AUTOSAR XML (schema 4-2-2)
package /STELLANTIS/EPT/ASWCs
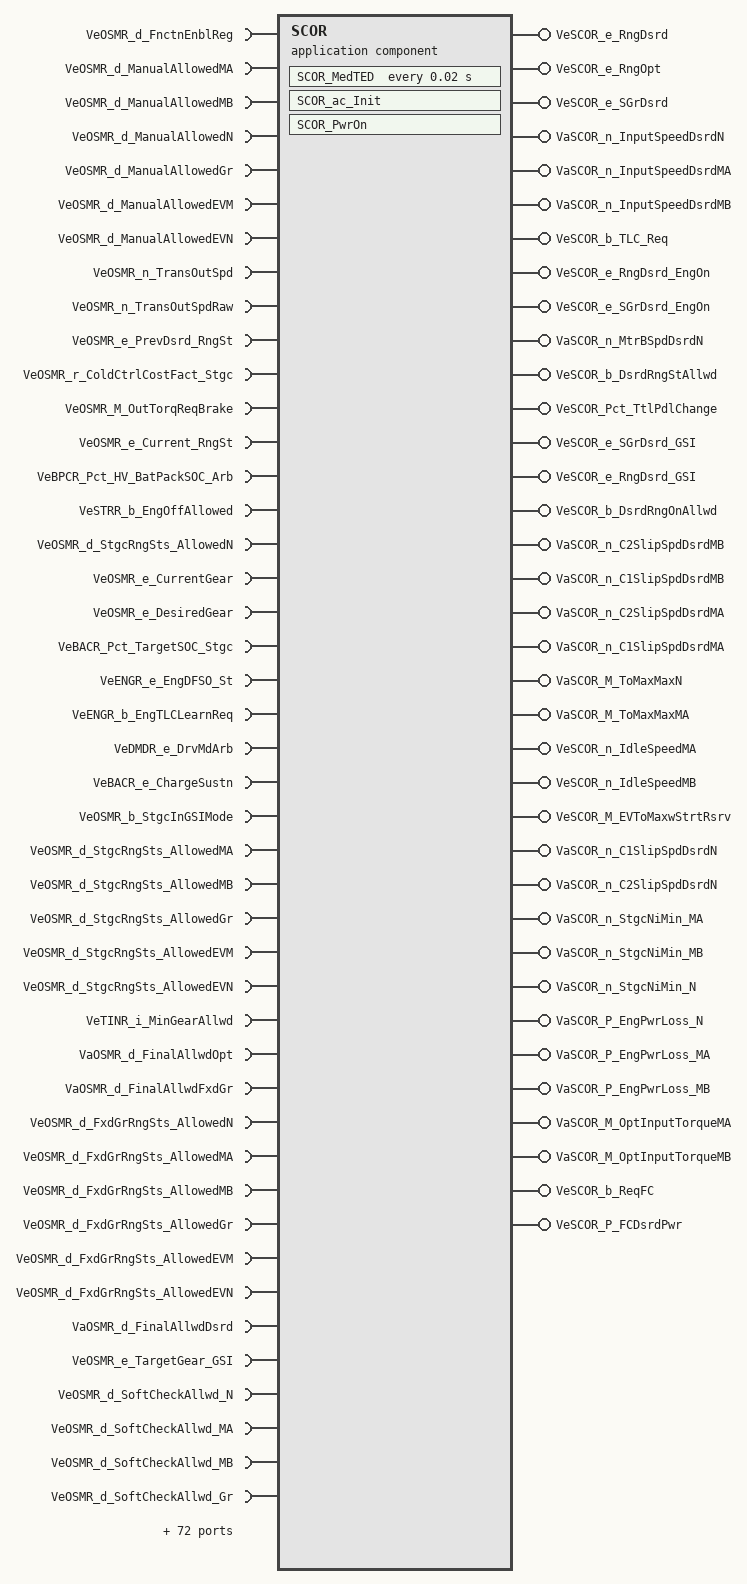
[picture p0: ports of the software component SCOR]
  application sw component type SCOR
    99 x require port:
      VeOSMR_d_FnctnEnblReg: nonqueued-receiver-com-spec{data-element=Value, init-value=0}, required-interface=VeOSMR_d_FnctnEnblReg
      VeOSMR_d_ManualAllowedMA: nonqueued-receiver-com-spec{data-element=Value, init-value=0}, required-interface=VeOSMR_d_ManualAllowedMA
      VeOSMR_d_ManualAllowedMB: nonqueued-receiver-com-spec{data-element=Value, init-value=0}, required-interface=VeOSMR_d_ManualAllowedMB
      VeOSMR_d_ManualAllowedN: nonqueued-receiver-com-spec{data-element=Value, init-value=0}, required-interface=VeOSMR_d_ManualAllowedN
      VeOSMR_d_ManualAllowedGr: nonqueued-receiver-com-spec{data-element=Value, init-value=0}, required-interface=VeOSMR_d_ManualAllowedGr
      VeOSMR_d_ManualAllowedEVM: nonqueued-receiver-com-spec{data-element=Value, init-value=0}, required-interface=VeOSMR_d_ManualAllowedEVM
      VeOSMR_d_ManualAllowedEVN: nonqueued-receiver-com-spec{data-element=Value, init-value=0}, required-interface=VeOSMR_d_ManualAllowedEVN
      VeOSMR_n_TransOutSpd: nonqueued-receiver-com-spec{data-element=Value, init-value=0}, required-interface=VeOSMR_n_TransOutSpd
      VeOSMR_n_TransOutSpdRaw: variation-point={short-label=vpVeOSMR_n_TransOutSpdRaw, sw-syscond=1}, nonqueued-receiver-com-spec{data-element=Value, init-value=0}, required-interface=VeOSMR_n_TransOutSpdRaw
      VeOSMR_e_PrevDsrd_RngSt: nonqueued-receiver-com-spec{data-element=Value, init-value=CeSCOR_e_SG_Neutral}, required-interface=VeOSMR_e_PrevDsrd_RngSt
      VeOSMR_r_ColdCtrlCostFact_Stgc: nonqueued-receiver-com-spec{data-element=Value, init-value=0}, required-interface=VeOSMR_r_ColdCtrlCostFact_Stgc
      VeOSMR_M_OutTorqReqBrake: nonqueued-receiver-com-spec{data-element=Value, init-value=0}, required-interface=VeOSMR_M_OutTorqReqBrake
      VeOSMR_e_Current_RngSt: nonqueued-receiver-com-spec{data-element=Value, init-value=CeSCOR_e_SG_Neutral}, required-interface=VeOSMR_e_Current_RngSt
      VeBPCR_Pct_HV_BatPackSOC_Arb: nonqueued-receiver-com-spec{data-element=Value, init-value=0}, required-interface=VeBPCR_Pct_HV_BatPackSOC_Arb
      VeSTRR_b_EngOffAllowed: nonqueued-receiver-com-spec{data-element=Value, init-value=0}, required-interface=VeSTRR_b_EngOffAllowed
      VeOSMR_d_StgcRngSts_AllowedN: nonqueued-receiver-com-spec{data-element=Value, init-value=0}, required-interface=VeOSMR_d_StgcRngSts_AllowedN
      VeOSMR_e_CurrentGear: nonqueued-receiver-com-spec{data-element=Value, init-value=CeTRNR_e_Neutral}, required-interface=VeOSMR_e_CurrentGear
      VeOSMR_e_DesiredGear: nonqueued-receiver-com-spec{data-element=Value, init-value=CeOHSR_e_SG_Reverse}, required-interface=VeOSMR_e_DesiredGear
      VeBACR_Pct_TargetSOC_Stgc: nonqueued-receiver-com-spec{data-element=Value, init-value=0}, required-interface=VeBACR_Pct_TargetSOC_Stgc
      VeENGR_e_EngDFSO_St: nonqueued-receiver-com-spec{data-element=Value, init-value=CeENGR_e_DFSO_Disabled}, required-interface=VeENGR_e_EngDFSO_St
      VeENGR_b_EngTLCLearnReq: nonqueued-receiver-com-spec{data-element=Value, init-value=0}, required-interface=VeENGR_b_EngTLCLearnReq
      VeDMDR_e_DrvMdArb: nonqueued-receiver-com-spec{data-element=Value, init-value=CeDMDR_e_NoDrvMd}, required-interface=VeDMDR_e_DrvMdArb
      VeBACR_e_ChargeSustn: nonqueued-receiver-com-spec{data-element=Value, init-value=CeBACR_e_ChargeSustaining}, required-interface=VeBACR_e_ChargeSustn
      VeOSMR_b_StgcInGSIMode: nonqueued-receiver-com-spec{data-element=Value, init-value=0}, required-interface=VeOSMR_b_StgcInGSIMode
      VeOSMR_d_StgcRngSts_AllowedMA: nonqueued-receiver-com-spec{data-element=Value, init-value=0}, required-interface=VeOSMR_d_StgcRngSts_AllowedMA
      VeOSMR_d_StgcRngSts_AllowedMB: nonqueued-receiver-com-spec{data-element=Value, init-value=0}, required-interface=VeOSMR_d_StgcRngSts_AllowedMB
      VeOSMR_d_StgcRngSts_AllowedGr: nonqueued-receiver-com-spec{data-element=Value, init-value=0}, required-interface=VeOSMR_d_StgcRngSts_AllowedGr
      VeOSMR_d_StgcRngSts_AllowedEVM: nonqueued-receiver-com-spec{data-element=Value, init-value=0}, required-interface=VeOSMR_d_StgcRngSts_AllowedEVM
      VeOSMR_d_StgcRngSts_AllowedEVN: nonqueued-receiver-com-spec{data-element=Value, init-value=0}, required-interface=VeOSMR_d_StgcRngSts_AllowedEVN
      VeTINR_i_MinGearAllwd: nonqueued-receiver-com-spec{data-element=Value, init-value=0}, required-interface=VeTINR_i_MinGearAllwd
      VaOSMR_d_FinalAllwdOpt: nonqueued-receiver-com-spec{data-element=Value, init-value=6 x 0}, required-interface=VaOSMR_d_FinalAllwdOpt
      VaOSMR_d_FinalAllwdFxdGr: nonqueued-receiver-com-spec{data-element=Value, init-value=6 x 0}, required-interface=VaOSMR_d_FinalAllwdFxdGr
      VeOSMR_d_FxdGrRngSts_AllowedN: nonqueued-receiver-com-spec{data-element=Value, init-value=0}, required-interface=VeOSMR_d_FxdGrRngSts_AllowedN
      VeOSMR_d_FxdGrRngSts_AllowedMA: nonqueued-receiver-com-spec{data-element=Value, init-value=0}, required-interface=VeOSMR_d_FxdGrRngSts_AllowedMA
      VeOSMR_d_FxdGrRngSts_AllowedMB: nonqueued-receiver-com-spec{data-element=Value, init-value=0}, required-interface=VeOSMR_d_FxdGrRngSts_AllowedMB
      VeOSMR_d_FxdGrRngSts_AllowedGr: nonqueued-receiver-com-spec{data-element=Value, init-value=0}, required-interface=VeOSMR_d_FxdGrRngSts_AllowedGr
      VeOSMR_d_FxdGrRngSts_AllowedEVM: nonqueued-receiver-com-spec{data-element=Value, init-value=0}, required-interface=VeOSMR_d_FxdGrRngSts_AllowedEVM
      VeOSMR_d_FxdGrRngSts_AllowedEVN: nonqueued-receiver-com-spec{data-element=Value, init-value=0}, required-interface=VeOSMR_d_FxdGrRngSts_AllowedEVN
      VaOSMR_d_FinalAllwdDsrd: nonqueued-receiver-com-spec{data-element=Value, init-value=6 x 0}, required-interface=VaOSMR_d_FinalAllwdDsrd
      VeOSMR_e_TargetGear_GSI: nonqueued-receiver-com-spec{data-element=Value, init-value=CeTRNR_e_Neutral}, required-interface=VeOSMR_e_TargetGear_GSI
      VeOSMR_d_SoftCheckAllwd_N: nonqueued-receiver-com-spec{data-element=Value, init-value=0}, required-interface=VeOSMR_d_SoftCheckAllwd_N
      VeOSMR_d_SoftCheckAllwd_MA: nonqueued-receiver-com-spec{data-element=Value, init-value=0}, required-interface=VeOSMR_d_SoftCheckAllwd_MA
      VeOSMR_d_SoftCheckAllwd_MB: nonqueued-receiver-com-spec{data-element=Value, init-value=0}, required-interface=VeOSMR_d_SoftCheckAllwd_MB
      VeOSMR_d_SoftCheckAllwd_Gr: nonqueued-receiver-com-spec{data-element=Value, init-value=0}, required-interface=VeOSMR_d_SoftCheckAllwd_Gr
      VeOSMR_d_SoftCheckAllwd_EVM: nonqueued-receiver-com-spec{data-element=Value, init-value=0}, required-interface=VeOSMR_d_SoftCheckAllwd_EVM
      VeOSMR_d_SoftCheckAllwd_EVN: nonqueued-receiver-com-spec{data-element=Value, init-value=0}, required-interface=VeOSMR_d_SoftCheckAllwd_EVN
      VeEOCR_r_CatTempMaintFact: nonqueued-receiver-com-spec{data-element=Value, init-value=0}, required-interface=VeEOCR_r_CatTempMaintFact
      VeOSMR_P_HVBatt_Bus_Min: nonqueued-receiver-com-spec{data-element=Value, init-value=0}, required-interface=VeOSMR_P_HVBatt_Bus_Min
      VeOSMR_P_HVBatt_Bus_Max: nonqueued-receiver-com-spec{data-element=Value, init-value=0}, required-interface=VeOSMR_P_HVBatt_Bus_Max
      VeOSMR_P_HV_AccPwr: nonqueued-receiver-com-spec{data-element=Value, init-value=0}, required-interface=VeOSMR_P_HV_AccPwr
      VeOSMR_M_OutTorqReqAccel: nonqueued-receiver-com-spec{data-element=Value, init-value=0}, required-interface=VeOSMR_M_OutTorqReqAccel
      VeAPSR_Pct_AccelPedalEffPosition: nonqueued-receiver-com-spec{data-element=Value, init-value=0}, required-interface=VeAPSR_Pct_AccelPedalEffPosition
      VaOSMR_i_MinGrPerRngSt: nonqueued-receiver-com-spec{data-element=Value, init-value=6 x 0}, required-interface=VaOSMR_i_MinGrPerRngSt
      VaOSMR_i_MaxGrPerRngSt: nonqueued-receiver-com-spec{data-element=Value, init-value=6 x 0}, required-interface=VaOSMR_i_MaxGrPerRngSt
      VeOSMR_b_1DOptEnbl: variation-point={short-label=vpVeOSMR_b_1DOptEnbl, sw-syscond=1}, nonqueued-receiver-com-spec{data-element=Value, init-value=0}, required-interface=VeOSMR_b_1DOptEnbl
      VeTHMR_P_FCPSThrmlPwr_MaxAllwd: nonqueued-receiver-com-spec{data-element=Value, init-value=0}, required-interface=VeTHMR_P_FCPSThrmlPwr_MaxAllwd
      VeFCPR_P_FCPS_ReqdMinFCPSPwr: nonqueued-receiver-com-spec{data-element=Value, init-value=0}, required-interface=VeFCPR_P_FCPS_ReqdMinFCPSPwr
      VeFCPR_P_FCPS_MaxAvailFCPSPwr: nonqueued-receiver-com-spec{data-element=Value, init-value=0}, required-interface=VeFCPR_P_FCPS_MaxAvailFCPSPwr
      VaOMAR_n_InputSpeedDsrdMA: nonqueued-receiver-com-spec{data-element=Value, init-value=9 x 0}, required-interface=VaOMAR_n_InputSpeedDsrdMA
      VaOMAR_M_OptInputTorqueMA: nonqueued-receiver-com-spec{data-element=Value, init-value=9 x 0}, required-interface=VaOMAR_M_OptInputTorqueMA
      VaOMAR_M_ToMaxMaxMA: nonqueued-receiver-com-spec{data-element=Value, init-value=9 x 0}, required-interface=VaOMAR_M_ToMaxMaxMA
      VaOMAR_n_C1SlipSpdDsrdMA: nonqueued-receiver-com-spec{data-element=Value, init-value=9 x 0}, required-interface=VaOMAR_n_C1SlipSpdDsrdMA
      VaOMAR_n_C2SlipSpdDsrdMA: nonqueued-receiver-com-spec{data-element=Value, init-value=9 x 0}, required-interface=VaOMAR_n_C2SlipSpdDsrdMA
      VaOMAR_OptBatPwrBrkRaw_MA: variation-point={short-label=vpVaOMAR_OptBatPwrBrkRaw_MA, sw-syscond=1}, nonqueued-receiver-com-spec{data-element=Value, init-value=9 x 0}, required-interface=VaOMAR_OptBatPwrBrkRaw_MA
      VaOMAR_n_StgcNiMin_MA: nonqueued-receiver-com-spec{data-element=Value, init-value=9 x 0}, required-interface=VaOMAR_n_StgcNiMin_MA
      VaOMAR_P_EngPwrLoss_MA: nonqueued-receiver-com-spec{data-element=Value, init-value=9 x 0}, required-interface=VaOMAR_P_EngPwrLoss_MA
      VaOMNR_PLossOptRaw_N: nonqueued-receiver-com-spec{data-element=Value, init-value=9 x 0}, required-interface=VaOMNR_PLossOptRaw_N
      VaOMAR_PLossOptRaw_MA: nonqueued-receiver-com-spec{data-element=Value, init-value=9 x 0}, required-interface=VaOMAR_PLossOptRaw_MA
      VaOMBR_PLossOptRaw_MB: nonqueued-receiver-com-spec{data-element=Value, init-value=9 x 0}, required-interface=VaOMBR_PLossOptRaw_MB
      VaOMBR_PLossOptRaw_MBNR: nonqueued-receiver-com-spec{data-element=Value, init-value=9 x 0}, required-interface=VaOMBR_PLossOptRaw_MBNR
      VaOGRR_PLossOptRaw_GrA: nonqueued-receiver-com-spec{data-element=Value, init-value=9 x 0}, required-interface=VaOGRR_PLossOptRaw_GrA
      VaOGRR_PLossOptRaw_Gr: nonqueued-receiver-com-spec{data-element=Value, init-value=9 x 0}, required-interface=VaOGRR_PLossOptRaw_Gr
      VaOEVR_PLossOptRaw_EVM: nonqueued-receiver-com-spec{data-element=Value, init-value=9 x 0}, required-interface=VaOEVR_PLossOptRaw_EVM
      VeOMAR_n_IdleSpeedMA: nonqueued-receiver-com-spec{data-element=Value, init-value=0}, required-interface=VeOMAR_n_IdleSpeedMA
      VaOMBR_n_InputSpeedDsrdMB: nonqueued-receiver-com-spec{data-element=Value, init-value=9 x 0}, required-interface=VaOMBR_n_InputSpeedDsrdMB
      VaOMBR_n_C1SlipSpdDsrdMB: nonqueued-receiver-com-spec{data-element=Value, init-value=9 x 0}, required-interface=VaOMBR_n_C1SlipSpdDsrdMB
      VaOMBR_n_C2SlipSpdDsrdMB: nonqueued-receiver-com-spec{data-element=Value, init-value=9 x 0}, required-interface=VaOMBR_n_C2SlipSpdDsrdMB
      VaOMBR_OptBatPwrBrkRaw_MBNR: variation-point={short-label=vpVaOMBR_OptBatPwrBrkRaw_MBNR, sw-syscond=1}, nonqueued-receiver-com-spec{data-element=Value, init-value=9 x 0}, required-interface=VaOMBR_OptBatPwrBrkRaw_MBNR
      VaOMBR_OptBatPwrBrkRaw_MB: variation-point={short-label=vpVaOMBR_OptBatPwrBrkRaw_MB, sw-syscond=1}, nonqueued-receiver-com-spec{data-element=Value, init-value=9 x 0}, required-interface=VaOMBR_OptBatPwrBrkRaw_MB
      VaOMBR_M_OptInputTorqueMB: nonqueued-receiver-com-spec{data-element=Value, init-value=9 x 0}, required-interface=VaOMBR_M_OptInputTorqueMB
      VaOMBR_n_StgcNiMin_MB: nonqueued-receiver-com-spec{data-element=Value, init-value=9 x 0}, required-interface=VaOMBR_n_StgcNiMin_MB
      VaOMBR_P_EngPwrLoss_MB: nonqueued-receiver-com-spec{data-element=Value, init-value=9 x 0}, required-interface=VaOMBR_P_EngPwrLoss_MB
      VeOMBR_n_IdleSpeedMB: nonqueued-receiver-com-spec{data-element=Value, init-value=0}, required-interface=VeOMBR_n_IdleSpeedMB
      VaOMNR_n_InputSpeedDsrdN: variation-point={short-label=vpVaOMNR_n_InputSpeedDsrdN, sw-syscond=1}, nonqueued-receiver-com-spec{data-element=Value, init-value=9 x 0}, required-interface=VaOMNR_n_InputSpeedDsrdN
      VaOMNR_n_MtrBSpdDsrdN: variation-point={short-label=vpVaOMNR_n_MtrBSpdDsrdN, sw-syscond=1}, nonqueued-receiver-com-spec{data-element=Value, init-value=9 x 0}, required-interface=VaOMNR_n_MtrBSpdDsrdN
      VaOMNR_n_C1SlipSpdDsrdN: nonqueued-receiver-com-spec{data-element=Value, init-value=9 x 0}, required-interface=VaOMNR_n_C1SlipSpdDsrdN
      VaOMNR_n_C2SlipSpdDsrdN: nonqueued-receiver-com-spec{data-element=Value, init-value=9 x 0}, required-interface=VaOMNR_n_C2SlipSpdDsrdN
      VaOMNR_M_ToMaxMaxN: nonqueued-receiver-com-spec{data-element=Value, init-value=9 x 0}, required-interface=VaOMNR_M_ToMaxMaxN
      VaOMNR_n_StgcNiMin_N: nonqueued-receiver-com-spec{data-element=Value, init-value=9 x 0}, required-interface=VaOMNR_n_StgcNiMin_N
      VaOMNR_M_OptInputTorqueN: variation-point={short-label=vpVaOMNR_M_OptInputTorqueN, sw-syscond=1}, nonqueued-receiver-com-spec{data-element=Value, init-value=9 x 0}, required-interface=VaOMNR_M_OptInputTorqueN
      VaOMNR_P_EngPwrLoss_N: variation-point={short-label=vpVaOMNR_P_EngPwrLoss_N, sw-syscond=1}, nonqueued-receiver-com-spec{data-element=Value, init-value=9 x 0}, required-interface=VaOMNR_P_EngPwrLoss_N
      VaOMNR_OptBatPwrBrkRaw_N: variation-point={short-label=vpVaOMNR_OptBatPwrBrkRaw_N, sw-syscond=1}, nonqueued-receiver-com-spec{data-element=Value, init-value=9 x 0}, required-interface=VaOMNR_OptBatPwrBrkRaw_N
      VaOGRR_OptBatPwrBrkRaw_GrA: variation-point={short-label=vpVaOGRR_OptBatPwrBrkRaw_GrA, sw-syscond=1}, nonqueued-receiver-com-spec{data-element=Value, init-value=9 x 0}, required-interface=VaOGRR_OptBatPwrBrkRaw_GrA
      VaOGRR_OptBatPwrBrkRaw_Gr: variation-point={short-label=vpVaOGRR_OptBatPwrBrkRaw_Gr, sw-syscond=1}, nonqueued-receiver-com-spec{data-element=Value, init-value=9 x 0}, required-interface=VaOGRR_OptBatPwrBrkRaw_Gr
      VaOEVR_PLossOptRaw_EVN: nonqueued-receiver-com-spec{data-element=Value, init-value=9 x 0}, required-interface=VaOEVR_PLossOptRaw_EVN
      VaOEVR_P_OptBattPwrEVM_Raw: nonqueued-receiver-com-spec{data-element=Value, init-value=9 x 0}, required-interface=VaOEVR_P_OptBattPwrEVM_Raw
      VaOEVR_P_OptBattPwrEVN_Raw: nonqueued-receiver-com-spec{data-element=Value, init-value=9 x 0}, required-interface=VaOEVR_P_OptBattPwrEVN_Raw
      VaOEVR_OptBatPwrBrkRaw_EVM: variation-point={short-label=vpVaOEVR_OptBatPwrBrkRaw_EVM, sw-syscond=1}, nonqueued-receiver-com-spec{data-element=Value, init-value=9 x 0}, required-interface=VaOEVR_OptBatPwrBrkRaw_EVM
      VaOEVR_OptBatPwrBrkRaw_EVN: variation-point={short-label=vpVaOEVR_OptBatPwrBrkRaw_EVN, sw-syscond=1}, nonqueued-receiver-com-spec{data-element=Value, init-value=9 x 0}, required-interface=VaOEVR_OptBatPwrBrkRaw_EVN
    36 x provide port:
      VeSCOR_e_RngDsrd: nonqueued-sender-com-spec{data-element=Value, init-value=CeSCOR_e_SG_Neutral}, provided-interface=VeSCOR_e_RngDsrd
      VeSCOR_e_RngOpt: nonqueued-sender-com-spec{data-element=Value, init-value=CeSCOR_e_SG_Neutral}, provided-interface=VeSCOR_e_RngOpt
      VeSCOR_e_SGrDsrd: nonqueued-sender-com-spec{data-element=Value, init-value=CeSCOR_e_SG_1}, provided-interface=VeSCOR_e_SGrDsrd
      VaSCOR_n_InputSpeedDsrdN: nonqueued-sender-com-spec{data-element=Value, init-value=9 x 0}, provided-interface=VaSCOR_n_InputSpeedDsrdN
      VaSCOR_n_InputSpeedDsrdMA: nonqueued-sender-com-spec{data-element=Value, init-value=9 x 0}, provided-interface=VaSCOR_n_InputSpeedDsrdMA
      VaSCOR_n_InputSpeedDsrdMB: nonqueued-sender-com-spec{data-element=Value, init-value=9 x 0}, provided-interface=VaSCOR_n_InputSpeedDsrdMB
      VeSCOR_b_TLC_Req: nonqueued-sender-com-spec{data-element=Value, init-value=0}, provided-interface=VeSCOR_b_TLC_Req
      VeSCOR_e_RngDsrd_EngOn: nonqueued-sender-com-spec{data-element=Value, init-value=CeSCOR_e_SG_Neutral}, provided-interface=VeSCOR_e_RngDsrd_EngOn
      VeSCOR_e_SGrDsrd_EngOn: nonqueued-sender-com-spec{data-element=Value, init-value=CeSCOR_e_SG_1}, provided-interface=VeSCOR_e_SGrDsrd_EngOn
      VaSCOR_n_MtrBSpdDsrdN: nonqueued-sender-com-spec{data-element=Value, init-value=9 x 0}, provided-interface=VaSCOR_n_MtrBSpdDsrdN
      VeSCOR_b_DsrdRngStAllwd: nonqueued-sender-com-spec{data-element=Value, init-value=0}, provided-interface=VeSCOR_b_DsrdRngStAllwd
      VeSCOR_Pct_TtlPdlChange: nonqueued-sender-com-spec{data-element=Value, init-value=0}, provided-interface=VeSCOR_Pct_TtlPdlChange
      VeSCOR_e_SGrDsrd_GSI: nonqueued-sender-com-spec{data-element=Value, init-value=CeSCOR_e_SG_1}, provided-interface=VeSCOR_e_SGrDsrd_GSI
      VeSCOR_e_RngDsrd_GSI: nonqueued-sender-com-spec{data-element=Value, init-value=CeSCOR_e_SG_Neutral}, provided-interface=VeSCOR_e_RngDsrd_GSI
      VeSCOR_b_DsrdRngOnAllwd: nonqueued-sender-com-spec{data-element=Value, init-value=0}, provided-interface=VeSCOR_b_DsrdRngOnAllwd
      VaSCOR_n_C2SlipSpdDsrdMB: nonqueued-sender-com-spec{data-element=Value, init-value=9 x 0}, provided-interface=VaSCOR_n_C2SlipSpdDsrdMB
      VaSCOR_n_C1SlipSpdDsrdMB: nonqueued-sender-com-spec{data-element=Value, init-value=9 x 0}, provided-interface=VaSCOR_n_C1SlipSpdDsrdMB
      VaSCOR_n_C2SlipSpdDsrdMA: nonqueued-sender-com-spec{data-element=Value, init-value=9 x 0}, provided-interface=VaSCOR_n_C2SlipSpdDsrdMA
      VaSCOR_n_C1SlipSpdDsrdMA: nonqueued-sender-com-spec{data-element=Value, init-value=9 x 0}, provided-interface=VaSCOR_n_C1SlipSpdDsrdMA
      VaSCOR_M_ToMaxMaxN: nonqueued-sender-com-spec{data-element=Value, init-value=9 x 0}, provided-interface=VaSCOR_M_ToMaxMaxN
      VaSCOR_M_ToMaxMaxMA: nonqueued-sender-com-spec{data-element=Value, init-value=9 x 0}, provided-interface=VaSCOR_M_ToMaxMaxMA
      VeSCOR_n_IdleSpeedMA: nonqueued-sender-com-spec{data-element=Value, init-value=0}, provided-interface=VeSCOR_n_IdleSpeedMA
      VeSCOR_n_IdleSpeedMB: nonqueued-sender-com-spec{data-element=Value, init-value=0}, provided-interface=VeSCOR_n_IdleSpeedMB
      VeSCOR_M_EVToMaxwStrtRsrv: nonqueued-sender-com-spec{data-element=Value, init-value=0}, provided-interface=VeSCOR_M_EVToMaxwStrtRsrv
      VaSCOR_n_C1SlipSpdDsrdN: nonqueued-sender-com-spec{data-element=Value, init-value=9 x 0}, provided-interface=VaSCOR_n_C1SlipSpdDsrdN
      VaSCOR_n_C2SlipSpdDsrdN: nonqueued-sender-com-spec{data-element=Value, init-value=9 x 0}, provided-interface=VaSCOR_n_C2SlipSpdDsrdN
      VaSCOR_n_StgcNiMin_MA: nonqueued-sender-com-spec{data-element=Value, init-value=9 x 0}, provided-interface=VaSCOR_n_StgcNiMin_MA
      VaSCOR_n_StgcNiMin_MB: nonqueued-sender-com-spec{data-element=Value, init-value=9 x 0}, provided-interface=VaSCOR_n_StgcNiMin_MB
      VaSCOR_n_StgcNiMin_N: nonqueued-sender-com-spec{data-element=Value, init-value=9 x 0}, provided-interface=VaSCOR_n_StgcNiMin_N
      VaSCOR_P_EngPwrLoss_N: nonqueued-sender-com-spec{data-element=Value, init-value=9 x 0}, provided-interface=VaSCOR_P_EngPwrLoss_N
      VaSCOR_P_EngPwrLoss_MA: nonqueued-sender-com-spec{data-element=Value, init-value=9 x 0}, provided-interface=VaSCOR_P_EngPwrLoss_MA
      VaSCOR_P_EngPwrLoss_MB: nonqueued-sender-com-spec{data-element=Value, init-value=9 x 0}, provided-interface=VaSCOR_P_EngPwrLoss_MB
      VaSCOR_M_OptInputTorqueMA: nonqueued-sender-com-spec{data-element=Value, init-value=9 x 0}, provided-interface=VaSCOR_M_OptInputTorqueMA
      VaSCOR_M_OptInputTorqueMB: nonqueued-sender-com-spec{data-element=Value, init-value=9 x 0}, provided-interface=VaSCOR_M_OptInputTorqueMB
      VeSCOR_b_ReqFC: nonqueued-sender-com-spec{data-element=Value, init-value=0}, provided-interface=VeSCOR_b_ReqFC
      VeSCOR_P_FCDsrdPwr: nonqueued-sender-com-spec{data-element=Value, init-value=0}, provided-interface=VeSCOR_P_FCDsrdPwr
    17 x require port:
      CaOPTR_r_ZeroArray: parameter-require-com-spec{init-value=CaOPTR_r_ZeroArray_CaOPTR_r_ZeroArray:[CaOPTR_r_ZeroArray_CaOPTR_r_ZeroArray_rt_Array_Float_9_1:0, CaOPTR_r_ZeroArray_CaOPTR_r_ZeroArray_rt_Array_Float_9_2:0, CaOPTR_r_ZeroArray_CaOPTR_r_ZeroArray_rt_Array_Float_9_3:0, CaOPTR_r_ZeroArray_CaOPTR_r_ZeroArray_rt_Array_Float_9_4:0, CaOPTR_r_ZeroArray_CaOPTR_r_ZeroArray_rt_Array_Float_9_5:0, CaOPTR_r_ZeroArray_CaOPTR_r_ZeroArray_rt_Array_Float_9_6:0, CaOPTR_r_ZeroArray_CaOPTR_r_ZeroArray_rt_Array_Float_9_7:0, CaOPTR_r_ZeroArray_CaOPTR_r_ZeroArray_rt_Array_Float_9_8:0, CaOPTR_r_ZeroArray_CaOPTR_r_ZeroArray_rt_Array_Float_9_9:0], parameter=CaOPTR_r_ZeroArray}, required-interface=CaOPTR_r_ZeroArray
      HaOPTR_n_InitInputSpdDsrdMA: parameter-require-com-spec{init-value=9 x 500, parameter=HaOPTR_n_InitInputSpdDsrdMA}, required-interface=HaOPTR_n_InitInputSpdDsrdMA
      HaOPTR_n_InitInputSpdDsrdMB: parameter-require-com-spec{init-value=9 x 500, parameter=HaOPTR_n_InitInputSpdDsrdMB}, required-interface=HaOPTR_n_InitInputSpdDsrdMB
      HaOPTR_n_InitInputSpdDsrdN: parameter-require-com-spec{init-value=9 x 500, parameter=HaOPTR_n_InitInputSpdDsrdN}, required-interface=HaOPTR_n_InitInputSpdDsrdN
      KeOPTR_P_DfltOptCost: parameter-require-com-spec{init-value=KeOPTR_P_DfltOptCost_KeOPTR_P_DfltOptCost:1000000, parameter=KeOPTR_P_DfltOptCost}, required-interface=KeOPTR_P_DfltOptCost
      HaOPTR_b_OptBatPwrBrk_EVM_Enbl: parameter-require-com-spec{init-value=HaOPTR_b_OptBatPwrBrk_EVM_Enbl_HaOPTR_b_OptBatPwrBrk_EVM_Enbl:[HaOPTR_b_OptBatPwrBrk_EVM_Enbl_HaOPTR_b_OptBatPwrBrk_EVM_Enbl_rt_Array_Boolean_9_1:0, HaOPTR_b_OptBatPwrBrk_EVM_Enbl_HaOPTR_b_OptBatPwrBrk_EVM_Enbl_rt_Array_Boolean_9_2:0, HaOPTR_b_OptBatPwrBrk_EVM_Enbl_HaOPTR_b_OptBatPwrBrk_EVM_Enbl_rt_Array_Boolean_9_3:0, HaOPTR_b_OptBatPwrBrk_EVM_Enbl_HaOPTR_b_OptBatPwrBrk_EVM_Enbl_rt_Array_Boolean_9_4:0, HaOPTR_b_OptBatPwrBrk_EVM_Enbl_HaOPTR_b_OptBatPwrBrk_EVM_Enbl_rt_Array_Boolean_9_5:0, HaOPTR_b_OptBatPwrBrk_EVM_Enbl_HaOPTR_b_OptBatPwrBrk_EVM_Enbl_rt_Array_Boolean_9_6:0, HaOPTR_b_OptBatPwrBrk_EVM_Enbl_HaOPTR_b_OptBatPwrBrk_EVM_Enbl_rt_Array_Boolean_9_7:0, HaOPTR_b_OptBatPwrBrk_EVM_Enbl_HaOPTR_b_OptBatPwrBrk_EVM_Enbl_rt_Array_Boolean_9_8:0, HaOPTR_b_OptBatPwrBrk_EVM_Enbl_HaOPTR_b_OptBatPwrBrk_EVM_Enbl_rt_Array_Boolean_9_9:0], parameter=HaOPTR_b_OptBatPwrBrk_EVM_Enbl}, required-interface=HaOPTR_b_OptBatPwrBrk_EVM_Enbl
      HaOPTR_b_OptBatPwrBrk_EVN_Enbl: parameter-require-com-spec{init-value=HaOPTR_b_OptBatPwrBrk_EVN_Enbl_HaOPTR_b_OptBatPwrBrk_EVN_Enbl:[HaOPTR_b_OptBatPwrBrk_EVN_Enbl_HaOPTR_b_OptBatPwrBrk_EVN_Enbl_rt_Array_Boolean_9_1:0, HaOPTR_b_OptBatPwrBrk_EVN_Enbl_HaOPTR_b_OptBatPwrBrk_EVN_Enbl_rt_Array_Boolean_9_2:0, HaOPTR_b_OptBatPwrBrk_EVN_Enbl_HaOPTR_b_OptBatPwrBrk_EVN_Enbl_rt_Array_Boolean_9_3:0, HaOPTR_b_OptBatPwrBrk_EVN_Enbl_HaOPTR_b_OptBatPwrBrk_EVN_Enbl_rt_Array_Boolean_9_4:0, HaOPTR_b_OptBatPwrBrk_EVN_Enbl_HaOPTR_b_OptBatPwrBrk_EVN_Enbl_rt_Array_Boolean_9_5:0, HaOPTR_b_OptBatPwrBrk_EVN_Enbl_HaOPTR_b_OptBatPwrBrk_EVN_Enbl_rt_Array_Boolean_9_6:0, HaOPTR_b_OptBatPwrBrk_EVN_Enbl_HaOPTR_b_OptBatPwrBrk_EVN_Enbl_rt_Array_Boolean_9_7:0, HaOPTR_b_OptBatPwrBrk_EVN_Enbl_HaOPTR_b_OptBatPwrBrk_EVN_Enbl_rt_Array_Boolean_9_8:0, HaOPTR_b_OptBatPwrBrk_EVN_Enbl_HaOPTR_b_OptBatPwrBrk_EVN_Enbl_rt_Array_Boolean_9_9:0], parameter=HaOPTR_b_OptBatPwrBrk_EVN_Enbl}, required-interface=HaOPTR_b_OptBatPwrBrk_EVN_Enbl
      HaOPTR_b_OptBatPwrBrk_Gr_Enbl: parameter-require-com-spec{init-value=HaOPTR_b_OptBatPwrBrk_Gr_Enbl_HaOPTR_b_OptBatPwrBrk_Gr_Enbl:[HaOPTR_b_OptBatPwrBrk_Gr_Enbl_HaOPTR_b_OptBatPwrBrk_Gr_Enbl_rt_Array_Boolean_9_1:0, HaOPTR_b_OptBatPwrBrk_Gr_Enbl_HaOPTR_b_OptBatPwrBrk_Gr_Enbl_rt_Array_Boolean_9_2:0, HaOPTR_b_OptBatPwrBrk_Gr_Enbl_HaOPTR_b_OptBatPwrBrk_Gr_Enbl_rt_Array_Boolean_9_3:0, HaOPTR_b_OptBatPwrBrk_Gr_Enbl_HaOPTR_b_OptBatPwrBrk_Gr_Enbl_rt_Array_Boolean_9_4:0, HaOPTR_b_OptBatPwrBrk_Gr_Enbl_HaOPTR_b_OptBatPwrBrk_Gr_Enbl_rt_Array_Boolean_9_5:0, HaOPTR_b_OptBatPwrBrk_Gr_Enbl_HaOPTR_b_OptBatPwrBrk_Gr_Enbl_rt_Array_Boolean_9_6:0, HaOPTR_b_OptBatPwrBrk_Gr_Enbl_HaOPTR_b_OptBatPwrBrk_Gr_Enbl_rt_Array_Boolean_9_7:0, HaOPTR_b_OptBatPwrBrk_Gr_Enbl_HaOPTR_b_OptBatPwrBrk_Gr_Enbl_rt_Array_Boolean_9_8:0, HaOPTR_b_OptBatPwrBrk_Gr_Enbl_HaOPTR_b_OptBatPwrBrk_Gr_Enbl_rt_Array_Boolean_9_9:0], parameter=HaOPTR_b_OptBatPwrBrk_Gr_Enbl}, required-interface=HaOPTR_b_OptBatPwrBrk_Gr_Enbl
      HaOPTR_b_OptBatPwrBrk_MA_Enbl: parameter-require-com-spec{init-value=HaOPTR_b_OptBatPwrBrk_MA_Enbl_HaOPTR_b_OptBatPwrBrk_MA_Enbl:[HaOPTR_b_OptBatPwrBrk_MA_Enbl_HaOPTR_b_OptBatPwrBrk_MA_Enbl_rt_Array_Boolean_9_1:0, HaOPTR_b_OptBatPwrBrk_MA_Enbl_HaOPTR_b_OptBatPwrBrk_MA_Enbl_rt_Array_Boolean_9_2:0, HaOPTR_b_OptBatPwrBrk_MA_Enbl_HaOPTR_b_OptBatPwrBrk_MA_Enbl_rt_Array_Boolean_9_3:0, HaOPTR_b_OptBatPwrBrk_MA_Enbl_HaOPTR_b_OptBatPwrBrk_MA_Enbl_rt_Array_Boolean_9_4:0, HaOPTR_b_OptBatPwrBrk_MA_Enbl_HaOPTR_b_OptBatPwrBrk_MA_Enbl_rt_Array_Boolean_9_5:0, HaOPTR_b_OptBatPwrBrk_MA_Enbl_HaOPTR_b_OptBatPwrBrk_MA_Enbl_rt_Array_Boolean_9_6:0, HaOPTR_b_OptBatPwrBrk_MA_Enbl_HaOPTR_b_OptBatPwrBrk_MA_Enbl_rt_Array_Boolean_9_7:0, HaOPTR_b_OptBatPwrBrk_MA_Enbl_HaOPTR_b_OptBatPwrBrk_MA_Enbl_rt_Array_Boolean_9_8:0, HaOPTR_b_OptBatPwrBrk_MA_Enbl_HaOPTR_b_OptBatPwrBrk_MA_Enbl_rt_Array_Boolean_9_9:0], parameter=HaOPTR_b_OptBatPwrBrk_MA_Enbl}, required-interface=HaOPTR_b_OptBatPwrBrk_MA_Enbl
      HaOPTR_b_OptBatPwrBrk_MB_Enbl: parameter-require-com-spec{init-value=HaOPTR_b_OptBatPwrBrk_MB_Enbl_HaOPTR_b_OptBatPwrBrk_MB_Enbl:[HaOPTR_b_OptBatPwrBrk_MB_Enbl_HaOPTR_b_OptBatPwrBrk_MB_Enbl_rt_Array_Boolean_9_1:0, HaOPTR_b_OptBatPwrBrk_MB_Enbl_HaOPTR_b_OptBatPwrBrk_MB_Enbl_rt_Array_Boolean_9_2:0, HaOPTR_b_OptBatPwrBrk_MB_Enbl_HaOPTR_b_OptBatPwrBrk_MB_Enbl_rt_Array_Boolean_9_3:0, HaOPTR_b_OptBatPwrBrk_MB_Enbl_HaOPTR_b_OptBatPwrBrk_MB_Enbl_rt_Array_Boolean_9_4:0, HaOPTR_b_OptBatPwrBrk_MB_Enbl_HaOPTR_b_OptBatPwrBrk_MB_Enbl_rt_Array_Boolean_9_5:0, HaOPTR_b_OptBatPwrBrk_MB_Enbl_HaOPTR_b_OptBatPwrBrk_MB_Enbl_rt_Array_Boolean_9_6:0, HaOPTR_b_OptBatPwrBrk_MB_Enbl_HaOPTR_b_OptBatPwrBrk_MB_Enbl_rt_Array_Boolean_9_7:0, HaOPTR_b_OptBatPwrBrk_MB_Enbl_HaOPTR_b_OptBatPwrBrk_MB_Enbl_rt_Array_Boolean_9_8:0, HaOPTR_b_OptBatPwrBrk_MB_Enbl_HaOPTR_b_OptBatPwrBrk_MB_Enbl_rt_Array_Boolean_9_9:0], parameter=HaOPTR_b_OptBatPwrBrk_MB_Enbl}, required-interface=HaOPTR_b_OptBatPwrBrk_MB_Enbl
      HaOPTR_b_OptBatPwrBrk_N_Enbl: parameter-require-com-spec{init-value=HaOPTR_b_OptBatPwrBrk_N_Enbl_HaOPTR_b_OptBatPwrBrk_N_Enbl:[HaOPTR_b_OptBatPwrBrk_N_Enbl_HaOPTR_b_OptBatPwrBrk_N_Enbl_rt_Array_Boolean_9_1:0, HaOPTR_b_OptBatPwrBrk_N_Enbl_HaOPTR_b_OptBatPwrBrk_N_Enbl_rt_Array_Boolean_9_2:0, HaOPTR_b_OptBatPwrBrk_N_Enbl_HaOPTR_b_OptBatPwrBrk_N_Enbl_rt_Array_Boolean_9_3:0, HaOPTR_b_OptBatPwrBrk_N_Enbl_HaOPTR_b_OptBatPwrBrk_N_Enbl_rt_Array_Boolean_9_4:0, HaOPTR_b_OptBatPwrBrk_N_Enbl_HaOPTR_b_OptBatPwrBrk_N_Enbl_rt_Array_Boolean_9_5:0, HaOPTR_b_OptBatPwrBrk_N_Enbl_HaOPTR_b_OptBatPwrBrk_N_Enbl_rt_Array_Boolean_9_6:0, HaOPTR_b_OptBatPwrBrk_N_Enbl_HaOPTR_b_OptBatPwrBrk_N_Enbl_rt_Array_Boolean_9_7:0, HaOPTR_b_OptBatPwrBrk_N_Enbl_HaOPTR_b_OptBatPwrBrk_N_Enbl_rt_Array_Boolean_9_8:0, HaOPTR_b_OptBatPwrBrk_N_Enbl_HaOPTR_b_OptBatPwrBrk_N_Enbl_rt_Array_Boolean_9_9:0], parameter=HaOPTR_b_OptBatPwrBrk_N_Enbl}, required-interface=HaOPTR_b_OptBatPwrBrk_N_Enbl
      HeOPTR_b_FixedGrDpndntRngSt_EVM: parameter-require-com-spec{init-value=HeOPTR_b_FixedGrDpndntRngSt_EVM_HeOPTR_b_FixedGrDpndntRngSt_EVM:0, parameter=HeOPTR_b_FixedGrDpndntRngSt_EVM}, required-interface=HeOPTR_b_FixedGrDpndntRngSt_EVM
      HeOPTR_b_FixedGrDpndntRngSt_EVN: parameter-require-com-spec{init-value=HeOPTR_b_FixedGrDpndntRngSt_EVN_HeOPTR_b_FixedGrDpndntRngSt_EVN:0, parameter=HeOPTR_b_FixedGrDpndntRngSt_EVN}, required-interface=HeOPTR_b_FixedGrDpndntRngSt_EVN
      HeOPTR_b_FixedGrDpndntRngSt_Gr: parameter-require-com-spec{init-value=HeOPTR_b_FixedGrDpndntRngSt_Gr_HeOPTR_b_FixedGrDpndntRngSt_Gr:0, parameter=HeOPTR_b_FixedGrDpndntRngSt_Gr}, required-interface=HeOPTR_b_FixedGrDpndntRngSt_Gr
      HeOPTR_b_FixedGrDpndntRngSt_MA: parameter-require-com-spec{init-value=HeOPTR_b_FixedGrDpndntRngSt_MA_HeOPTR_b_FixedGrDpndntRngSt_MA:0, parameter=HeOPTR_b_FixedGrDpndntRngSt_MA}, required-interface=HeOPTR_b_FixedGrDpndntRngSt_MA
      HeOPTR_b_FixedGrDpndntRngSt_MB: parameter-require-com-spec{init-value=HeOPTR_b_FixedGrDpndntRngSt_MB_HeOPTR_b_FixedGrDpndntRngSt_MB:0, parameter=HeOPTR_b_FixedGrDpndntRngSt_MB}, required-interface=HeOPTR_b_FixedGrDpndntRngSt_MB
      HeOPTR_b_FixedGrDpndntRngSt_N_GA: parameter-require-com-spec{init-value=HeOPTR_b_FixedGrDpndntRngSt_N_GA_HeOPTR_b_FixedGrDpndntRngSt_N_GA:0, parameter=HeOPTR_b_FixedGrDpndntRngSt_N_GA}, required-interface=HeOPTR_b_FixedGrDpndntRngSt_N_GA
    behavior IB_SCOR: data-type-mapping=msADTtoIDTMapping, handle-termination-and-restart=NO-SUPPORT
      timing event Event_MedTED: start-on-event=SCOR_MedTED, period=0.02
      init event Event_SCOR_ac_Init: start-on-event=SCOR_ac_Init
      init event Event_PwrOn: start-on-event=SCOR_PwrOn
      explicit-inter-runnable-variables:
        12 x data, all with category=VALUE, sw-calibration-access=READ-ONLY, type=SInt16, init-value=0:
          LeSCOR_e_InitSGDsrd_N_write_IRV
          LeSCOR_e_InitSGDsrd_MA_write_IRV
          LeSCOR_e_InitSGDsrd_Gr_write_IRV
          LeSCOR_e_InitSGDsrd_MB_write_IRV
          LeSCOR_e_InitSGDsrd_EVM_write_IRV
          LeSCOR_e_InitSGDsrd_EVN_write_IRV
          LeSCOR_e_InitSGDsrd_N1_write_IRV
          LeSCOR_e_InitSGDsrd_MA1_write_IRV
          LeSCOR_e_InitSGDsrd_MB1_write_IRV
          LeSCOR_e_InitSGDsrd_Gr1_write_IRV
          LeSCOR_e_InitSGDsrd_EVM1_write_IRV
          LeSCOR_e_InitSGDsrd_EVN1_write_IRV
      runnable SCOR_ac_Init
        data-send-points:
          27 x access:
            OUT_VeSCOR_e_RngDsrd_Value: accessed-variable=VeSCOR_e_RngDsrd.Value
            OUT_VeSCOR_e_RngOpt_Value: accessed-variable=VeSCOR_e_RngOpt.Value
            OUT_VeSCOR_e_SGrDsrd_Value: accessed-variable=VeSCOR_e_SGrDsrd.Value
            OUT_VaSCOR_n_InputSpeedDsrdN_Value: accessed-variable=VaSCOR_n_InputSpeedDsrdN.Value
            OUT_VaSCOR_n_InputSpeedDsrdMA_Value: accessed-variable=VaSCOR_n_InputSpeedDsrdMA.Value
            OUT_VaSCOR_n_InputSpeedDsrdMB_Value: accessed-variable=VaSCOR_n_InputSpeedDsrdMB.Value
            OUT_VeSCOR_e_RngDsrd_EngOn_Value: accessed-variable=VeSCOR_e_RngDsrd_EngOn.Value
            OUT_VeSCOR_e_SGrDsrd_EngOn_Value: accessed-variable=VeSCOR_e_SGrDsrd_EngOn.Value
            OUT_VaSCOR_n_MtrBSpdDsrdN_Value: accessed-variable=VaSCOR_n_MtrBSpdDsrdN.Value
            OUT_VeSCOR_e_SGrDsrd_GSI_Value: accessed-variable=VeSCOR_e_SGrDsrd_GSI.Value
            OUT_VeSCOR_e_RngDsrd_GSI_Value: accessed-variable=VeSCOR_e_RngDsrd_GSI.Value
            OUT_VaSCOR_n_C2SlipSpdDsrdMB_Value: accessed-variable=VaSCOR_n_C2SlipSpdDsrdMB.Value
            OUT_VaSCOR_n_C1SlipSpdDsrdMB_Value: accessed-variable=VaSCOR_n_C1SlipSpdDsrdMB.Value
            OUT_VaSCOR_n_C2SlipSpdDsrdMA_Value: accessed-variable=VaSCOR_n_C2SlipSpdDsrdMA.Value
            OUT_VaSCOR_n_C1SlipSpdDsrdMA_Value: accessed-variable=VaSCOR_n_C1SlipSpdDsrdMA.Value
            OUT_VaSCOR_M_ToMaxMaxN_Value: accessed-variable=VaSCOR_M_ToMaxMaxN.Value
            OUT_VaSCOR_M_ToMaxMaxMA_Value: accessed-variable=VaSCOR_M_ToMaxMaxMA.Value
            OUT_VaSCOR_n_C1SlipSpdDsrdN_Value: accessed-variable=VaSCOR_n_C1SlipSpdDsrdN.Value
            OUT_VaSCOR_n_C2SlipSpdDsrdN_Value: accessed-variable=VaSCOR_n_C2SlipSpdDsrdN.Value
            OUT_VaSCOR_n_StgcNiMin_MA_Value: accessed-variable=VaSCOR_n_StgcNiMin_MA.Value
            OUT_VaSCOR_n_StgcNiMin_MB_Value: accessed-variable=VaSCOR_n_StgcNiMin_MB.Value
            OUT_VaSCOR_n_StgcNiMin_N_Value: accessed-variable=VaSCOR_n_StgcNiMin_N.Value
            OUT_VaSCOR_P_EngPwrLoss_N_Value: accessed-variable=VaSCOR_P_EngPwrLoss_N.Value
            OUT_VaSCOR_P_EngPwrLoss_MA_Value: accessed-variable=VaSCOR_P_EngPwrLoss_MA.Value
            OUT_VaSCOR_P_EngPwrLoss_MB_Value: accessed-variable=VaSCOR_P_EngPwrLoss_MB.Value
            OUT_VaSCOR_M_OptInputTorqueMA_Value: accessed-variable=VaSCOR_M_OptInputTorqueMA.Value
            OUT_VaSCOR_M_OptInputTorqueMB_Value: accessed-variable=VaSCOR_M_OptInputTorqueMB.Value
      runnable SCOR_PwrOn
        data-send-points:
          36 x access:
            OUT_VaSCOR_n_InputSpeedDsrdMA_Value: accessed-variable=VaSCOR_n_InputSpeedDsrdMA.Value
            OUT_VaSCOR_n_C2SlipSpdDsrdMB_Value: accessed-variable=VaSCOR_n_C2SlipSpdDsrdMB.Value
            OUT_VaSCOR_n_C1SlipSpdDsrdMB_Value: accessed-variable=VaSCOR_n_C1SlipSpdDsrdMB.Value
            OUT_VeSCOR_e_SGrDsrd_GSI_Value: accessed-variable=VeSCOR_e_SGrDsrd_GSI.Value
            OUT_VaSCOR_n_C1SlipSpdDsrdMA_Value: accessed-variable=VaSCOR_n_C1SlipSpdDsrdMA.Value
            OUT_VaSCOR_n_C2SlipSpdDsrdMA_Value: accessed-variable=VaSCOR_n_C2SlipSpdDsrdMA.Value
            OUT_VaSCOR_M_ToMaxMaxMA_Value: accessed-variable=VaSCOR_M_ToMaxMaxMA.Value
            OUT_VaSCOR_M_ToMaxMaxN_Value: accessed-variable=VaSCOR_M_ToMaxMaxN.Value
            OUT_VeSCOR_n_IdleSpeedMA_Value: accessed-variable=VeSCOR_n_IdleSpeedMA.Value
            OUT_VeSCOR_n_IdleSpeedMB_Value: accessed-variable=VeSCOR_n_IdleSpeedMB.Value
            OUT_VaSCOR_n_C1SlipSpdDsrdN_Value: accessed-variable=VaSCOR_n_C1SlipSpdDsrdN.Value
            OUT_VaSCOR_n_InputSpeedDsrdMB_Value: accessed-variable=VaSCOR_n_InputSpeedDsrdMB.Value
            OUT_VaSCOR_n_C2SlipSpdDsrdN_Value: accessed-variable=VaSCOR_n_C2SlipSpdDsrdN.Value
            OUT_VeSCOR_M_EVToMaxwStrtRsrv_Value: accessed-variable=VeSCOR_M_EVToMaxwStrtRsrv.Value
            OUT_VaSCOR_n_StgcNiMin_MA_Value: accessed-variable=VaSCOR_n_StgcNiMin_MA.Value
            OUT_VaSCOR_n_StgcNiMin_MB_Value: accessed-variable=VaSCOR_n_StgcNiMin_MB.Value
            OUT_VaSCOR_n_StgcNiMin_N_Value: accessed-variable=VaSCOR_n_StgcNiMin_N.Value
            OUT_VaSCOR_P_EngPwrLoss_N_Value: accessed-variable=VaSCOR_P_EngPwrLoss_N.Value
            OUT_VaSCOR_P_EngPwrLoss_MA_Value: accessed-variable=VaSCOR_P_EngPwrLoss_MA.Value
            OUT_VaSCOR_P_EngPwrLoss_MB_Value: accessed-variable=VaSCOR_P_EngPwrLoss_MB.Value
            OUT_VeSCOR_e_RngDsrd_Value: accessed-variable=VeSCOR_e_RngDsrd.Value
            OUT_VeSCOR_e_RngOpt_Value: accessed-variable=VeSCOR_e_RngOpt.Value
            OUT_VeSCOR_e_SGrDsrd_Value: accessed-variable=VeSCOR_e_SGrDsrd.Value
            OUT_VaSCOR_n_InputSpeedDsrdN_Value: accessed-variable=VaSCOR_n_InputSpeedDsrdN.Value
            OUT_VeSCOR_e_SGrDsrd_EngOn_Value: accessed-variable=VeSCOR_e_SGrDsrd_EngOn.Value
            OUT_VeSCOR_e_RngDsrd_EngOn_Value: accessed-variable=VeSCOR_e_RngDsrd_EngOn.Value
            OUT_VaSCOR_n_MtrBSpdDsrdN_Value: accessed-variable=VaSCOR_n_MtrBSpdDsrdN.Value
            OUT_VeSCOR_b_TLC_Req_Value: accessed-variable=VeSCOR_b_TLC_Req.Value
            OUT_VeSCOR_b_DsrdRngStAllwd_Value: accessed-variable=VeSCOR_b_DsrdRngStAllwd.Value
            OUT_VeSCOR_Pct_TtlPdlChange_Value: accessed-variable=VeSCOR_Pct_TtlPdlChange.Value
            OUT_VeSCOR_e_RngDsrd_GSI_Value: accessed-variable=VeSCOR_e_RngDsrd_GSI.Value
            OUT_VeSCOR_b_DsrdRngOnAllwd_Value: accessed-variable=VeSCOR_b_DsrdRngOnAllwd.Value
            OUT_VaSCOR_M_OptInputTorqueMA_Value: accessed-variable=VaSCOR_M_OptInputTorqueMA.Value
            OUT_VaSCOR_M_OptInputTorqueMB_Value: accessed-variable=VaSCOR_M_OptInputTorqueMB.Value
            OUT_VeSCOR_b_ReqFC_Value: accessed-variable=VeSCOR_b_ReqFC.Value
            OUT_VeSCOR_P_FCDsrdPwr_Value: accessed-variable=VeSCOR_P_FCDsrdPwr.Value
        4 x parameter access:
          CALPRM_CaOPTR_r_ZeroArray_CaOPTR_r_ZeroArray: accessed-parameter=CaOPTR_r_ZeroArray.CaOPTR_r_ZeroArray
          CALPRM_HaOPTR_n_InitInputSpdDsrdMA_HaOPTR_n_InitInputSpdDsrdMA: accessed-parameter=HaOPTR_n_InitInputSpdDsrdMA.HaOPTR_n_InitInputSpdDsrdMA
          CALPRM_HaOPTR_n_InitInputSpdDsrdMB_HaOPTR_n_InitInputSpdDsrdMB: accessed-parameter=HaOPTR_n_InitInputSpdDsrdMB.HaOPTR_n_InitInputSpdDsrdMB
          CALPRM_HaOPTR_n_InitInputSpdDsrdN_HaOPTR_n_InitInputSpdDsrdN: accessed-parameter=HaOPTR_n_InitInputSpdDsrdN.HaOPTR_n_InitInputSpdDsrdN
        written-local-variables:
          12 x access:
            WV_LeSCOR_e_InitSGDsrd_EVM1_write_IRV: accessed-variable=LeSCOR_e_InitSGDsrd_EVM1_write_IRV
            WV_LeSCOR_e_InitSGDsrd_EVM_write_IRV: accessed-variable=LeSCOR_e_InitSGDsrd_EVM_write_IRV
            WV_LeSCOR_e_InitSGDsrd_EVN1_write_IRV: accessed-variable=LeSCOR_e_InitSGDsrd_EVN1_write_IRV
            WV_LeSCOR_e_InitSGDsrd_EVN_write_IRV: accessed-variable=LeSCOR_e_InitSGDsrd_EVN_write_IRV
            WV_LeSCOR_e_InitSGDsrd_Gr1_write_IRV: accessed-variable=LeSCOR_e_InitSGDsrd_Gr1_write_IRV
            WV_LeSCOR_e_InitSGDsrd_Gr_write_IRV: accessed-variable=LeSCOR_e_InitSGDsrd_Gr_write_IRV
            WV_LeSCOR_e_InitSGDsrd_MA1_write_IRV: accessed-variable=LeSCOR_e_InitSGDsrd_MA1_write_IRV
            WV_LeSCOR_e_InitSGDsrd_MA_write_IRV: accessed-variable=LeSCOR_e_InitSGDsrd_MA_write_IRV
            WV_LeSCOR_e_InitSGDsrd_MB1_write_IRV: accessed-variable=LeSCOR_e_InitSGDsrd_MB1_write_IRV
            WV_LeSCOR_e_InitSGDsrd_MB_write_IRV: accessed-variable=LeSCOR_e_InitSGDsrd_MB_write_IRV
            WV_LeSCOR_e_InitSGDsrd_N1_write_IRV: accessed-variable=LeSCOR_e_InitSGDsrd_N1_write_IRV
            WV_LeSCOR_e_InitSGDsrd_N_write_IRV: accessed-variable=LeSCOR_e_InitSGDsrd_N_write_IRV
      runnable SCOR_MedTED
        data-receive-point-by-arguments:
          94 x access:
            IN_VaOEVR_OptBatPwrBrkRaw_EVM_Value: accessed-variable=VaOEVR_OptBatPwrBrkRaw_EVM.Value, variation-point={short-label=vpIN_VaOEVR_OptBatPwrBrkRaw_EVM_Value, sw-syscond=1}
            IN_VaOEVR_OptBatPwrBrkRaw_EVN_Value: accessed-variable=VaOEVR_OptBatPwrBrkRaw_EVN.Value, variation-point={short-label=vpIN_VaOEVR_OptBatPwrBrkRaw_EVN_Value, sw-syscond=1}
            IN_VaOEVR_PLossOptRaw_EVM_Value: accessed-variable=VaOEVR_PLossOptRaw_EVM.Value
            IN_VaOEVR_PLossOptRaw_EVN_Value: accessed-variable=VaOEVR_PLossOptRaw_EVN.Value
            IN_VaOEVR_P_OptBattPwrEVM_Raw_Value: accessed-variable=VaOEVR_P_OptBattPwrEVM_Raw.Value
            IN_VaOEVR_P_OptBattPwrEVN_Raw_Value: accessed-variable=VaOEVR_P_OptBattPwrEVN_Raw.Value
            IN_VaOGRR_OptBatPwrBrkRaw_Gr_Value: accessed-variable=VaOGRR_OptBatPwrBrkRaw_Gr.Value, variation-point={short-label=vpIN_VaOGRR_OptBatPwrBrkRaw_Gr_Value, sw-syscond=1}
            IN_VaOGRR_OptBatPwrBrkRaw_GrA_Value: accessed-variable=VaOGRR_OptBatPwrBrkRaw_GrA.Value, variation-point={short-label=vpIN_VaOGRR_OptBatPwrBrkRaw_GrA_Value, sw-syscond=1}
            IN_VaOGRR_PLossOptRaw_Gr_Value: accessed-variable=VaOGRR_PLossOptRaw_Gr.Value
            IN_VaOGRR_PLossOptRaw_GrA_Value: accessed-variable=VaOGRR_PLossOptRaw_GrA.Value
            IN_VaOMAR_M_OptInputTorqueMA_Value: accessed-variable=VaOMAR_M_OptInputTorqueMA.Value
            IN_VaOMAR_M_ToMaxMaxMA_Value: accessed-variable=VaOMAR_M_ToMaxMaxMA.Value
            IN_VaOMAR_OptBatPwrBrkRaw_MA_Value: accessed-variable=VaOMAR_OptBatPwrBrkRaw_MA.Value, variation-point={short-label=vpIN_VaOMAR_OptBatPwrBrkRaw_MA_Value, sw-syscond=1}
            IN_VaOMAR_PLossOptRaw_MA_Value: accessed-variable=VaOMAR_PLossOptRaw_MA.Value
            IN_VaOMAR_P_EngPwrLoss_MA_Value: accessed-variable=VaOMAR_P_EngPwrLoss_MA.Value
            IN_VaOMAR_n_C1SlipSpdDsrdMA_Value: accessed-variable=VaOMAR_n_C1SlipSpdDsrdMA.Value
            IN_VaOMAR_n_C2SlipSpdDsrdMA_Value: accessed-variable=VaOMAR_n_C2SlipSpdDsrdMA.Value
            IN_VaOMAR_n_InputSpeedDsrdMA_Value: accessed-variable=VaOMAR_n_InputSpeedDsrdMA.Value
            IN_VaOMAR_n_StgcNiMin_MA_Value: accessed-variable=VaOMAR_n_StgcNiMin_MA.Value
            IN_VaOMBR_M_OptInputTorqueMB_Value: accessed-variable=VaOMBR_M_OptInputTorqueMB.Value
            IN_VaOMBR_OptBatPwrBrkRaw_MB_Value: accessed-variable=VaOMBR_OptBatPwrBrkRaw_MB.Value, variation-point={short-label=vpIN_VaOMBR_OptBatPwrBrkRaw_MB_Value, sw-syscond=1}
            IN_VaOMBR_OptBatPwrBrkRaw_MBNR_Value: accessed-variable=VaOMBR_OptBatPwrBrkRaw_MBNR.Value, variation-point={short-label=vpIN_VaOMBR_OptBatPwrBrkRaw_MBNR_Value, sw-syscond=1}
            IN_VaOMBR_PLossOptRaw_MB_Value: accessed-variable=VaOMBR_PLossOptRaw_MB.Value
            IN_VaOMBR_PLossOptRaw_MBNR_Value: accessed-variable=VaOMBR_PLossOptRaw_MBNR.Value
            IN_VaOMBR_P_EngPwrLoss_MB_Value: accessed-variable=VaOMBR_P_EngPwrLoss_MB.Value
            IN_VaOMBR_n_C1SlipSpdDsrdMB_Value: accessed-variable=VaOMBR_n_C1SlipSpdDsrdMB.Value
            IN_VaOMBR_n_C2SlipSpdDsrdMB_Value: accessed-variable=VaOMBR_n_C2SlipSpdDsrdMB.Value
            IN_VaOMBR_n_InputSpeedDsrdMB_Value: accessed-variable=VaOMBR_n_InputSpeedDsrdMB.Value
            IN_VaOMBR_n_StgcNiMin_MB_Value: accessed-variable=VaOMBR_n_StgcNiMin_MB.Value
            IN_VaOMNR_M_ToMaxMaxN_Value: accessed-variable=VaOMNR_M_ToMaxMaxN.Value
            IN_VaOMNR_OptBatPwrBrkRaw_N_Value: accessed-variable=VaOMNR_OptBatPwrBrkRaw_N.Value, variation-point={short-label=vpIN_VaOMNR_OptBatPwrBrkRaw_N_Value, sw-syscond=1}
            IN_VaOMNR_PLossOptRaw_N_Value: accessed-variable=VaOMNR_PLossOptRaw_N.Value
            IN_VaOMNR_P_EngPwrLoss_N_Value: accessed-variable=VaOMNR_P_EngPwrLoss_N.Value, variation-point={short-label=vpIN_VaOMNR_P_EngPwrLoss_N_Value, sw-syscond=1}
            IN_VaOMNR_n_C1SlipSpdDsrdN_Value: accessed-variable=VaOMNR_n_C1SlipSpdDsrdN.Value
            IN_VaOMNR_n_C2SlipSpdDsrdN_Value: accessed-variable=VaOMNR_n_C2SlipSpdDsrdN.Value
            IN_VaOMNR_n_InputSpeedDsrdN_Value: accessed-variable=VaOMNR_n_InputSpeedDsrdN.Value, variation-point={short-label=vpIN_VaOMNR_n_InputSpeedDsrdN_Value, sw-syscond=1}
            IN_VaOMNR_n_MtrBSpdDsrdN_Value: accessed-variable=VaOMNR_n_MtrBSpdDsrdN.Value, variation-point={short-label=vpIN_VaOMNR_n_MtrBSpdDsrdN_Value, sw-syscond=1}
            IN_VaOMNR_n_StgcNiMin_N_Value: accessed-variable=VaOMNR_n_StgcNiMin_N.Value
            IN_VaOSMR_d_FinalAllwdDsrd_Value: accessed-variable=VaOSMR_d_FinalAllwdDsrd.Value
            IN_VaOSMR_d_FinalAllwdFxdGr_Value: accessed-variable=VaOSMR_d_FinalAllwdFxdGr.Value
            IN_VaOSMR_d_FinalAllwdOpt_Value: accessed-variable=VaOSMR_d_FinalAllwdOpt.Value
            IN_VaOSMR_i_MaxGrPerRngSt_Value: accessed-variable=VaOSMR_i_MaxGrPerRngSt.Value
            IN_VaOSMR_i_MinGrPerRngSt_Value: accessed-variable=VaOSMR_i_MinGrPerRngSt.Value
            IN_VeAPSR_Pct_AccelPedalEffPosition_Value: accessed-variable=VeAPSR_Pct_AccelPedalEffPosition.Value
            IN_VeBACR_Pct_TargetSOC_Stgc_Value: accessed-variable=VeBACR_Pct_TargetSOC_Stgc.Value
            IN_VeBACR_e_ChargeSustn_Value: accessed-variable=VeBACR_e_ChargeSustn.Value
            IN_VeBPCR_Pct_HV_BatPackSOC_Arb_Value: accessed-variable=VeBPCR_Pct_HV_BatPackSOC_Arb.Value
            IN_VeDMDR_e_DrvMdArb_Value: accessed-variable=VeDMDR_e_DrvMdArb.Value
            IN_VeENGR_b_EngTLCLearnReq_Value: accessed-variable=VeENGR_b_EngTLCLearnReq.Value
            IN_VeENGR_e_EngDFSO_St_Value: accessed-variable=VeENGR_e_EngDFSO_St.Value
            IN_VeEOCR_r_CatTempMaintFact_Value: accessed-variable=VeEOCR_r_CatTempMaintFact.Value
            IN_VeFCPR_P_FCPS_MaxAvailFCPSPwr_Value: accessed-variable=VeFCPR_P_FCPS_MaxAvailFCPSPwr.Value
            IN_VeFCPR_P_FCPS_ReqdMinFCPSPwr_Value: accessed-variable=VeFCPR_P_FCPS_ReqdMinFCPSPwr.Value
            IN_VeOMAR_n_IdleSpeedMA_Value: accessed-variable=VeOMAR_n_IdleSpeedMA.Value
            IN_VeOMBR_n_IdleSpeedMB_Value: accessed-variable=VeOMBR_n_IdleSpeedMB.Value
            IN_VeOSMR_M_OutTorqReqBrake_Value: accessed-variable=VeOSMR_M_OutTorqReqBrake.Value
            IN_VeOSMR_b_1DOptEnbl_Value: accessed-variable=VeOSMR_b_1DOptEnbl.Value, variation-point={short-label=vpIN_VeOSMR_b_1DOptEnbl_Value, sw-syscond=1}
            IN_VeOSMR_b_StgcInGSIMode_Value: accessed-variable=VeOSMR_b_StgcInGSIMode.Value
            IN_VeOSMR_d_FnctnEnblReg_Value: accessed-variable=VeOSMR_d_FnctnEnblReg.Value
            IN_VeOSMR_d_FxdGrRngSts_AllowedEVM_Value: accessed-variable=VeOSMR_d_FxdGrRngSts_AllowedEVM.Value
            IN_VeOSMR_d_FxdGrRngSts_AllowedEVN_Value: accessed-variable=VeOSMR_d_FxdGrRngSts_AllowedEVN.Value
            IN_VeOSMR_d_FxdGrRngSts_AllowedGr_Value: accessed-variable=VeOSMR_d_FxdGrRngSts_AllowedGr.Value
            IN_VeOSMR_d_FxdGrRngSts_AllowedMA_Value: accessed-variable=VeOSMR_d_FxdGrRngSts_AllowedMA.Value
            IN_VeOSMR_d_FxdGrRngSts_AllowedMB_Value: accessed-variable=VeOSMR_d_FxdGrRngSts_AllowedMB.Value
            IN_VeOSMR_d_FxdGrRngSts_AllowedN_Value: accessed-variable=VeOSMR_d_FxdGrRngSts_AllowedN.Value
            IN_VeOSMR_d_ManualAllowedEVM_Value: accessed-variable=VeOSMR_d_ManualAllowedEVM.Value
            IN_VeOSMR_d_ManualAllowedEVN_Value: accessed-variable=VeOSMR_d_ManualAllowedEVN.Value
            IN_VeOSMR_d_ManualAllowedGr_Value: accessed-variable=VeOSMR_d_ManualAllowedGr.Value
            IN_VeOSMR_d_ManualAllowedMA_Value: accessed-variable=VeOSMR_d_ManualAllowedMA.Value
            IN_VeOSMR_d_ManualAllowedMB_Value: accessed-variable=VeOSMR_d_ManualAllowedMB.Value
            IN_VeOSMR_d_ManualAllowedN_Value: accessed-variable=VeOSMR_d_ManualAllowedN.Value
            IN_VeOSMR_d_SoftCheckAllwd_EVM_Value: accessed-variable=VeOSMR_d_SoftCheckAllwd_EVM.Value
            IN_VeOSMR_d_SoftCheckAllwd_EVN_Value: accessed-variable=VeOSMR_d_SoftCheckAllwd_EVN.Value
            IN_VeOSMR_d_SoftCheckAllwd_Gr_Value: accessed-variable=VeOSMR_d_SoftCheckAllwd_Gr.Value
            IN_VeOSMR_d_SoftCheckAllwd_MA_Value: accessed-variable=VeOSMR_d_SoftCheckAllwd_MA.Value
            IN_VeOSMR_d_SoftCheckAllwd_MB_Value: accessed-variable=VeOSMR_d_SoftCheckAllwd_MB.Value
            IN_VeOSMR_d_SoftCheckAllwd_N_Value: accessed-variable=VeOSMR_d_SoftCheckAllwd_N.Value
            IN_VeOSMR_d_StgcRngSts_AllowedEVM_Value: accessed-variable=VeOSMR_d_StgcRngSts_AllowedEVM.Value
            IN_VeOSMR_d_StgcRngSts_AllowedEVN_Value: accessed-variable=VeOSMR_d_StgcRngSts_AllowedEVN.Value
            IN_VeOSMR_d_StgcRngSts_AllowedGr_Value: accessed-variable=VeOSMR_d_StgcRngSts_AllowedGr.Value
            IN_VeOSMR_d_StgcRngSts_AllowedMA_Value: accessed-variable=VeOSMR_d_StgcRngSts_AllowedMA.Value
            IN_VeOSMR_d_StgcRngSts_AllowedMB_Value: accessed-variable=VeOSMR_d_StgcRngSts_AllowedMB.Value
            IN_VeOSMR_d_StgcRngSts_AllowedN_Value: accessed-variable=VeOSMR_d_StgcRngSts_AllowedN.Value
            IN_VeOSMR_e_CurrentGear_Value: accessed-variable=VeOSMR_e_CurrentGear.Value
            IN_VeOSMR_e_Current_RngSt_Value: accessed-variable=VeOSMR_e_Current_RngSt.Value
            IN_VeOSMR_e_DesiredGear_Value: accessed-variable=VeOSMR_e_DesiredGear.Value
            IN_VeOSMR_e_PrevDsrd_RngSt_Value: accessed-variable=VeOSMR_e_PrevDsrd_RngSt.Value
            IN_VeOSMR_e_TargetGear_GSI_Value: accessed-variable=VeOSMR_e_TargetGear_GSI.Value
            IN_VeOSMR_n_TransOutSpd_Value: accessed-variable=VeOSMR_n_TransOutSpd.Value
            IN_VeOSMR_n_TransOutSpdRaw_Value: accessed-variable=VeOSMR_n_TransOutSpdRaw.Value, variation-point={short-label=vpIN_VeOSMR_n_TransOutSpdRaw_Value, sw-syscond=1}
            IN_VeOSMR_r_ColdCtrlCostFact_Stgc_Value: accessed-variable=VeOSMR_r_ColdCtrlCostFact_Stgc.Value
            IN_VeSTRR_b_EngOffAllowed_Value: accessed-variable=VeSTRR_b_EngOffAllowed.Value
            IN_VeTHMR_P_FCPSThrmlPwr_MaxAllwd_Value: accessed-variable=VeTHMR_P_FCPSThrmlPwr_MaxAllwd.Value
            IN_VeTINR_i_MinGearAllwd_Value: accessed-variable=VeTINR_i_MinGearAllwd.Value
        data-send-points:
          36 x access:
            OUT_VeSCOR_b_TLC_Req_Value: accessed-variable=VeSCOR_b_TLC_Req.Value
            OUT_VeSCOR_Pct_TtlPdlChange_Value: accessed-variable=VeSCOR_Pct_TtlPdlChange.Value
            OUT_VaSCOR_n_InputSpeedDsrdMA_Value: accessed-variable=VaSCOR_n_InputSpeedDsrdMA.Value
            OUT_VaSCOR_n_C2SlipSpdDsrdMB_Value: accessed-variable=VaSCOR_n_C2SlipSpdDsrdMB.Value
            OUT_VaSCOR_n_C1SlipSpdDsrdMB_Value: accessed-variable=VaSCOR_n_C1SlipSpdDsrdMB.Value
            OUT_VeSCOR_e_SGrDsrd_GSI_Value: accessed-variable=VeSCOR_e_SGrDsrd_GSI.Value
            OUT_VaSCOR_n_C1SlipSpdDsrdMA_Value: accessed-variable=VaSCOR_n_C1SlipSpdDsrdMA.Value
            OUT_VaSCOR_n_C2SlipSpdDsrdMA_Value: accessed-variable=VaSCOR_n_C2SlipSpdDsrdMA.Value
            OUT_VaSCOR_M_ToMaxMaxMA_Value: accessed-variable=VaSCOR_M_ToMaxMaxMA.Value
            OUT_VaSCOR_M_ToMaxMaxN_Value: accessed-variable=VaSCOR_M_ToMaxMaxN.Value
            OUT_VeSCOR_n_IdleSpeedMA_Value: accessed-variable=VeSCOR_n_IdleSpeedMA.Value
            OUT_VeSCOR_n_IdleSpeedMB_Value: accessed-variable=VeSCOR_n_IdleSpeedMB.Value
            OUT_VaSCOR_n_C1SlipSpdDsrdN_Value: accessed-variable=VaSCOR_n_C1SlipSpdDsrdN.Value
            OUT_VaSCOR_n_InputSpeedDsrdMB_Value: accessed-variable=VaSCOR_n_InputSpeedDsrdMB.Value
            OUT_VaSCOR_n_C2SlipSpdDsrdN_Value: accessed-variable=VaSCOR_n_C2SlipSpdDsrdN.Value
            OUT_VeSCOR_M_EVToMaxwStrtRsrv_Value: accessed-variable=VeSCOR_M_EVToMaxwStrtRsrv.Value
            OUT_VaSCOR_n_StgcNiMin_MA_Value: accessed-variable=VaSCOR_n_StgcNiMin_MA.Value
            OUT_VaSCOR_n_StgcNiMin_MB_Value: accessed-variable=VaSCOR_n_StgcNiMin_MB.Value
            OUT_VaSCOR_n_StgcNiMin_N_Value: accessed-variable=VaSCOR_n_StgcNiMin_N.Value
            OUT_VaSCOR_P_EngPwrLoss_N_Value: accessed-variable=VaSCOR_P_EngPwrLoss_N.Value
            OUT_VaSCOR_P_EngPwrLoss_MA_Value: accessed-variable=VaSCOR_P_EngPwrLoss_MA.Value
            OUT_VaSCOR_P_EngPwrLoss_MB_Value: accessed-variable=VaSCOR_P_EngPwrLoss_MB.Value
            OUT_VeSCOR_e_RngDsrd_Value: accessed-variable=VeSCOR_e_RngDsrd.Value
            OUT_VeSCOR_e_RngOpt_Value: accessed-variable=VeSCOR_e_RngOpt.Value
            OUT_VeSCOR_e_SGrDsrd_Value: accessed-variable=VeSCOR_e_SGrDsrd.Value
            OUT_VaSCOR_n_InputSpeedDsrdN_Value: accessed-variable=VaSCOR_n_InputSpeedDsrdN.Value
            OUT_VeSCOR_e_SGrDsrd_EngOn_Value: accessed-variable=VeSCOR_e_SGrDsrd_EngOn.Value
            OUT_VeSCOR_e_RngDsrd_EngOn_Value: accessed-variable=VeSCOR_e_RngDsrd_EngOn.Value
            OUT_VaSCOR_n_MtrBSpdDsrdN_Value: accessed-variable=VaSCOR_n_MtrBSpdDsrdN.Value
            OUT_VeSCOR_b_DsrdRngStAllwd_Value: accessed-variable=VeSCOR_b_DsrdRngStAllwd.Value
            OUT_VeSCOR_e_RngDsrd_GSI_Value: accessed-variable=VeSCOR_e_RngDsrd_GSI.Value
            OUT_VeSCOR_b_DsrdRngOnAllwd_Value: accessed-variable=VeSCOR_b_DsrdRngOnAllwd.Value
            OUT_VaSCOR_M_OptInputTorqueMA_Value: accessed-variable=VaSCOR_M_OptInputTorqueMA.Value
            OUT_VaSCOR_M_OptInputTorqueMB_Value: accessed-variable=VaSCOR_M_OptInputTorqueMB.Value
            OUT_VeSCOR_b_ReqFC_Value: accessed-variable=VeSCOR_b_ReqFC.Value
            OUT_VeSCOR_P_FCDsrdPwr_Value: accessed-variable=VeSCOR_P_FCDsrdPwr.Value
        13 x parameter access:
          CALPRM_HaOPTR_b_OptBatPwrBrk_EVM_Enbl_HaOPTR_b_OptBatPwrBrk_EVM_Enbl: accessed-parameter=HaOPTR_b_OptBatPwrBrk_EVM_Enbl.HaOPTR_b_OptBatPwrBrk_EVM_Enbl, variation-point={short-label=vpCALPRM_HaOPTR_b_OptBatPwrBrk_EVM_Enbl_HaOPTR_b_OptBatPwrBrk_EVM_Enbl, sw-syscond=1}
          CALPRM_HaOPTR_b_OptBatPwrBrk_EVN_Enbl_HaOPTR_b_OptBatPwrBrk_EVN_Enbl: accessed-parameter=HaOPTR_b_OptBatPwrBrk_EVN_Enbl.HaOPTR_b_OptBatPwrBrk_EVN_Enbl, variation-point={short-label=vpCALPRM_HaOPTR_b_OptBatPwrBrk_EVN_Enbl_HaOPTR_b_OptBatPwrBrk_EVN_Enbl, sw-syscond=1}
          CALPRM_HaOPTR_b_OptBatPwrBrk_Gr_Enbl_HaOPTR_b_OptBatPwrBrk_Gr_Enbl: accessed-parameter=HaOPTR_b_OptBatPwrBrk_Gr_Enbl.HaOPTR_b_OptBatPwrBrk_Gr_Enbl, variation-point={short-label=vpCALPRM_HaOPTR_b_OptBatPwrBrk_Gr_Enbl_HaOPTR_b_OptBatPwrBrk_Gr_Enbl, sw-syscond=1}
          CALPRM_HaOPTR_b_OptBatPwrBrk_MA_Enbl_HaOPTR_b_OptBatPwrBrk_MA_Enbl: accessed-parameter=HaOPTR_b_OptBatPwrBrk_MA_Enbl.HaOPTR_b_OptBatPwrBrk_MA_Enbl, variation-point={short-label=vpCALPRM_HaOPTR_b_OptBatPwrBrk_MA_Enbl_HaOPTR_b_OptBatPwrBrk_MA_Enbl, sw-syscond=1}
          CALPRM_HaOPTR_b_OptBatPwrBrk_MB_Enbl_HaOPTR_b_OptBatPwrBrk_MB_Enbl: accessed-parameter=HaOPTR_b_OptBatPwrBrk_MB_Enbl.HaOPTR_b_OptBatPwrBrk_MB_Enbl, variation-point={short-label=vpCALPRM_HaOPTR_b_OptBatPwrBrk_MB_Enbl_HaOPTR_b_OptBatPwrBrk_MB_Enbl, sw-syscond=1}
          CALPRM_HaOPTR_b_OptBatPwrBrk_N_Enbl_HaOPTR_b_OptBatPwrBrk_N_Enbl: accessed-parameter=HaOPTR_b_OptBatPwrBrk_N_Enbl.HaOPTR_b_OptBatPwrBrk_N_Enbl, variation-point={short-label=vpCALPRM_HaOPTR_b_OptBatPwrBrk_N_Enbl_HaOPTR_b_OptBatPwrBrk_N_Enbl, sw-syscond=1}
          CALPRM_HeOPTR_b_FixedGrDpndntRngSt_EVM_HeOPTR_b_FixedGrDpndntRngSt_EVM: accessed-parameter=HeOPTR_b_FixedGrDpndntRngSt_EVM.HeOPTR_b_FixedGrDpndntRngSt_EVM
          CALPRM_HeOPTR_b_FixedGrDpndntRngSt_EVN_HeOPTR_b_FixedGrDpndntRngSt_EVN: accessed-parameter=HeOPTR_b_FixedGrDpndntRngSt_EVN.HeOPTR_b_FixedGrDpndntRngSt_EVN
          CALPRM_HeOPTR_b_FixedGrDpndntRngSt_Gr_HeOPTR_b_FixedGrDpndntRngSt_Gr: accessed-parameter=HeOPTR_b_FixedGrDpndntRngSt_Gr.HeOPTR_b_FixedGrDpndntRngSt_Gr
          CALPRM_HeOPTR_b_FixedGrDpndntRngSt_MA_HeOPTR_b_FixedGrDpndntRngSt_MA: accessed-parameter=HeOPTR_b_FixedGrDpndntRngSt_MA.HeOPTR_b_FixedGrDpndntRngSt_MA
          CALPRM_HeOPTR_b_FixedGrDpndntRngSt_MB_HeOPTR_b_FixedGrDpndntRngSt_MB: accessed-parameter=HeOPTR_b_FixedGrDpndntRngSt_MB.HeOPTR_b_FixedGrDpndntRngSt_MB
          CALPRM_HeOPTR_b_FixedGrDpndntRngSt_N_GA_HeOPTR_b_FixedGrDpndntRngSt_N_GA: accessed-parameter=HeOPTR_b_FixedGrDpndntRngSt_N_GA.HeOPTR_b_FixedGrDpndntRngSt_N_GA
          CALPRM_KeOPTR_P_DfltOptCost_KeOPTR_P_DfltOptCost: accessed-parameter=KeOPTR_P_DfltOptCost.KeOPTR_P_DfltOptCost
        read-local-variables:
          12 x access:
            RV_LeSCOR_e_InitSGDsrd_EVM1_write_IRV: accessed-variable=LeSCOR_e_InitSGDsrd_EVM1_write_IRV
            RV_LeSCOR_e_InitSGDsrd_EVM_write_IRV: accessed-variable=LeSCOR_e_InitSGDsrd_EVM_write_IRV
            RV_LeSCOR_e_InitSGDsrd_EVN1_write_IRV: accessed-variable=LeSCOR_e_InitSGDsrd_EVN1_write_IRV
            RV_LeSCOR_e_InitSGDsrd_EVN_write_IRV: accessed-variable=LeSCOR_e_InitSGDsrd_EVN_write_IRV
            RV_LeSCOR_e_InitSGDsrd_Gr1_write_IRV: accessed-variable=LeSCOR_e_InitSGDsrd_Gr1_write_IRV
            RV_LeSCOR_e_InitSGDsrd_Gr_write_IRV: accessed-variable=LeSCOR_e_InitSGDsrd_Gr_write_IRV
            RV_LeSCOR_e_InitSGDsrd_MA1_write_IRV: accessed-variable=LeSCOR_e_InitSGDsrd_MA1_write_IRV
            RV_LeSCOR_e_InitSGDsrd_MA_write_IRV: accessed-variable=LeSCOR_e_InitSGDsrd_MA_write_IRV
            RV_LeSCOR_e_InitSGDsrd_MB1_write_IRV: accessed-variable=LeSCOR_e_InitSGDsrd_MB1_write_IRV
            RV_LeSCOR_e_InitSGDsrd_MB_write_IRV: accessed-variable=LeSCOR_e_InitSGDsrd_MB_write_IRV
            RV_LeSCOR_e_InitSGDsrd_N1_write_IRV: accessed-variable=LeSCOR_e_InitSGDsrd_N1_write_IRV
            RV_LeSCOR_e_InitSGDsrd_N_write_IRV: accessed-variable=LeSCOR_e_InitSGDsrd_N_write_IRV
        written-local-variables:
          12 x access:
            WV_LeSCOR_e_InitSGDsrd_EVM_write_IRV: accessed-variable=LeSCOR_e_InitSGDsrd_EVM_write_IRV
            WV_LeSCOR_e_InitSGDsrd_EVN_write_IRV: accessed-variable=LeSCOR_e_InitSGDsrd_EVN_write_IRV
            WV_LeSCOR_e_InitSGDsrd_EVM1_write_IRV: accessed-variable=LeSCOR_e_InitSGDsrd_EVM1_write_IRV
            WV_LeSCOR_e_InitSGDsrd_EVN1_write_IRV: accessed-variable=LeSCOR_e_InitSGDsrd_EVN1_write_IRV
            WV_LeSCOR_e_InitSGDsrd_Gr1_write_IRV: accessed-variable=LeSCOR_e_InitSGDsrd_Gr1_write_IRV
            WV_LeSCOR_e_InitSGDsrd_N1_write_IRV: accessed-variable=LeSCOR_e_InitSGDsrd_N1_write_IRV
            WV_LeSCOR_e_InitSGDsrd_MA1_write_IRV: accessed-variable=LeSCOR_e_InitSGDsrd_MA1_write_IRV
            WV_LeSCOR_e_InitSGDsrd_MB1_write_IRV: accessed-variable=LeSCOR_e_InitSGDsrd_MB1_write_IRV
            WV_LeSCOR_e_InitSGDsrd_Gr_write_IRV: accessed-variable=LeSCOR_e_InitSGDsrd_Gr_write_IRV
            WV_LeSCOR_e_InitSGDsrd_N_write_IRV: accessed-variable=LeSCOR_e_InitSGDsrd_N_write_IRV
            WV_LeSCOR_e_InitSGDsrd_MA_write_IRV: accessed-variable=LeSCOR_e_InitSGDsrd_MA_write_IRV
            WV_LeSCOR_e_InitSGDsrd_MB_write_IRV: accessed-variable=LeSCOR_e_InitSGDsrd_MB_write_IRV
      5 x variation point proxy, all with category=CONDITION:
        Variant_OPTR_EnblEVToMaxwStrtRsrv: condition-access=0
        Variant_OPTR_EnblGrA: condition-access=0
        Variant_OPTR_OptBatPwrBrkEnbl: condition-access=1
        Variant_SCOR_EnblStratNRGHyst: condition-access=1
        Variant_SCOR_FUNC_PxPy_4: condition-access=0
